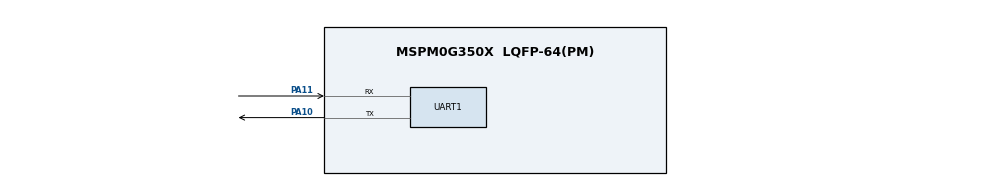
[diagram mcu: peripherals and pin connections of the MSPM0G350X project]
/**
 * @cliArgs --device "MSPM0G350X" --part "Default" --package "LQFP-64(PM)" --product "mspm0_sdk@2.02.00.05"
 * @versions {"tool":"1.21.1+3772"}
 */

/**
 * Import the modules used in this configuration.
 */
const GPIO    = scripting.addModule("/ti/driverlib/GPIO", {}, false);
const GPIO1   = GPIO.addInstance();
const SYSCTL  = scripting.addModule("/ti/driverlib/SYSCTL");
const SYSTICK = scripting.addModule("/ti/driverlib/SYSTICK");
const UART    = scripting.addModule("/ti/driverlib/UART", {}, false);
const UART1   = UART.addInstance();

/**
 * Write custom configuration values to the imported modules.
 */
const gate7  = system.clockTree["MFCLKGATE"];
gate7.enable = true;

const multiplier2         = system.clockTree["PLL_QDIV"];
multiplier2.multiplyValue = 5;

GPIO1.$name                          = "I2C";
GPIO1.port                           = "PORTA";
GPIO1.associatedPins.create(2);
GPIO1.associatedPins[0].$name        = "SDA";
GPIO1.associatedPins[0].initialValue = "SET";
GPIO1.associatedPins[1].$name        = "SCL";
GPIO1.associatedPins[1].initialValue = "SET";

const Board = scripting.addModule("/ti/driverlib/Board", {}, false);

SYSCTL.forceDefaultClkConfig = true;
SYSCTL.clockTreeEn           = true;

SYSTICK.periodEnable  = true;
SYSTICK.systickEnable = true;
SYSTICK.period        = 32;

UART1.$name                    = "UART_0";
UART1.uartClkSrc               = "MFCLK";
UART1.enabledInterrupts        = ["RX"];
UART1.targetBaudRate           = 115200;
UART1.peripheral.rxPin.$assign = "PA11";
UART1.peripheral.txPin.$assign = "PA10";
UART1.txPinConfig.$name        = "ti_driverlib_gpio_GPIOPinGeneric0";
UART1.rxPinConfig.$name        = "ti_driverlib_gpio_GPIOPinGeneric1";

/**
 * Pinmux solution for unlocked pins/peripherals. This ensures that minor changes to the automatic solver in a future
 * version of the tool will not impact the pinmux you originally saw.  These lines can be completely deleted in order to
 * re-solve from scratch.
 */
GPIO1.associatedPins[0].pin.$suggestSolution = "PA13";
GPIO1.associatedPins[1].pin.$suggestSolution = "PA12";
Board.peripheral.$suggestSolution            = "DEBUGSS";
Board.peripheral.swclkPin.$suggestSolution   = "PA20";
Board.peripheral.swdioPin.$suggestSolution   = "PA19";
UART1.peripheral.$suggestSolution            = "UART0";
